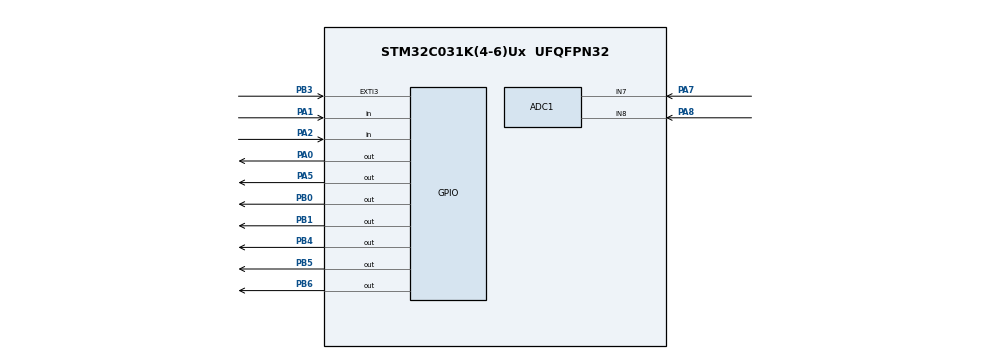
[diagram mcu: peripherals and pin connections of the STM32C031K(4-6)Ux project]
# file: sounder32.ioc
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ADC1.Channel-0\#ChannelRegularConversion=ADC_CHANNEL_7
ADC1.NbrOfConversionFlag=1
ADC1.Rank-0\#ChannelRegularConversion=1
ADC1.SamplingTime-0\#ChannelRegularConversion=ADC_SAMPLINGTIME_COMMON_1
ADC1.SelectedChannel=ADC_CHANNEL_7|ADC_CHANNEL_8
ADC1.master=1
Mcu.Family=STM32C0
Mcu.Name=STM32C031K(4-6)Ux
Mcu.Package=UFQFPN32
PA0.Signal=GPIO_Output
PA1.Signal=GPIO_Input
PA2.Signal=GPIO_Input
PA5.Signal=GPIO_Output
PA7.Mode=IN7
PA7.Signal=ADC1_IN7
PA8.Mode=IN8
PA8.Signal=ADC1_IN8
PB0.Signal=GPIO_Output
PB1.Signal=GPIO_Output
PB3.Signal=GPXTI3
PB4.Signal=GPIO_Output
PB5.Signal=GPIO_Output
PB6.Signal=GPIO_Output
PB7.Signal=I2C1_SDA
PB8.Signal=I2C1_SCL
ProjectManager.HeapSize=0x200
ProjectManager.StackSize=0x400
ProjectManager.TargetToolchain=MDK-ARM V5.32
RCC.ADCFreq_Value=12000000
RCC.AHBFreq_Value=12000000
RCC.CortexFreq_Value=12000000
RCC.EXTERNAL_CLOCK_VALUE=12288000
RCC.HCLKFreq_Value=12000000
RCC.HSE_VALUE=8000000
RCC.HSI_VALUE=48000000
RCC.LSE_VALUE=32768
RCC.SYSCLKFreq_VALUE=12000000
TIM1.Channel-Output\ Compare1\ No\ Output=TIM_CHANNEL_1
TIM3.Channel-Output\ Compare2\ No\ Output=TIM_CHANNEL_2
VP_TIM1_VS_ClockSourceINT.Mode=Internal
VP_TIM1_VS_no_output1.Mode=Output Compare1 No Output
VP_TIM3_VS_ClockSourceINT.Mode=Internal
VP_TIM3_VS_no_output2.Mode=Output Compare2 No Output
board=custom

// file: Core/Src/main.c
/* USER CODE BEGIN Header */
/**
  ******************************************************************************
  * @file           : main.c
  * @brief          : Main program body
  ******************************************************************************
  * @attention
  *
  * Copyright (c) 2023 STMicroelectronics.
  * All rights reserved.
  *
  * This software is licensed under terms that can be found in the LICENSE file
  * in the root directory of this software component.
  * If no LICENSE file comes with this software, it is provided AS-IS.
  *
  ******************************************************************************
  */
/* USER CODE END Header */
#include "main.h"

ADC_HandleTypeDef hadc1;

TIM_HandleTypeDef htim1;
TIM_HandleTypeDef htim3;

extern void main_8(void);

void SystemClock_Config(void);
static void MX_GPIO_Init(void);
static void MX_ADC1_Init(void);
static void MX_TIM3_Init(void);
static void MX_TIM1_Init(void);

int main(void)
{

  /* MCU Configuration--------------------------------------------------------*/

  /* Reset of all peripherals, Initializes the Flash interface and the Systick. */
  HAL_Init();

  /* Configure the system clock */
  SystemClock_Config();

  /* Initialize all configured peripherals */
  MX_GPIO_Init();
  MX_ADC1_Init();
  MX_TIM3_Init();
  MX_TIM1_Init();
  /* USER CODE BEGIN 2 */

	main_8();

  /* USER CODE END 2 */

  /* Infinite loop */
  while (1)
  {

  }
}

void SystemClock_Config(void)
{
  RCC_OscInitTypeDef RCC_OscInitStruct = {0};
  RCC_ClkInitTypeDef RCC_ClkInitStruct = {0};

  /** Initializes the RCC Oscillators according to the specified parameters
  * in the RCC_OscInitTypeDef structure.
  */
  RCC_OscInitStruct.OscillatorType = RCC_OSCILLATORTYPE_HSI;
  RCC_OscInitStruct.HSIState = RCC_HSI_ON;
  RCC_OscInitStruct.HSIDiv = RCC_HSI_DIV4;
  RCC_OscInitStruct.HSICalibrationValue = RCC_HSICALIBRATION_DEFAULT;
  if (HAL_RCC_OscConfig(&RCC_OscInitStruct) != HAL_OK)
  {
    Error_Handler();
  }

  /** Initializes the CPU, AHB and APB buses clocks
  */
  RCC_ClkInitStruct.ClockType = RCC_CLOCKTYPE_HCLK|RCC_CLOCKTYPE_SYSCLK
                              |RCC_CLOCKTYPE_PCLK1;
  RCC_ClkInitStruct.SYSCLKSource = RCC_SYSCLKSOURCE_HSI;
  RCC_ClkInitStruct.SYSCLKDivider = RCC_SYSCLK_DIV1;
  RCC_ClkInitStruct.AHBCLKDivider = RCC_HCLK_DIV1;
  RCC_ClkInitStruct.APB1CLKDivider = RCC_APB1_DIV1;

  if (HAL_RCC_ClockConfig(&RCC_ClkInitStruct, FLASH_LATENCY_0) != HAL_OK)
  {
    Error_Handler();
  }
}

static void MX_ADC1_Init(void)
{

  ADC_ChannelConfTypeDef sConfig = {0};

  /** Configure the global features of the ADC (Clock, Resolution, Data Alignment and number of conversion)
  */
  hadc1.Instance = ADC1;
  hadc1.Init.ClockPrescaler = ADC_CLOCK_SYNC_PCLK_DIV2;
  hadc1.Init.Resolution = ADC_RESOLUTION_12B;
  hadc1.Init.DataAlign = ADC_DATAALIGN_RIGHT;
  hadc1.Init.ScanConvMode = ADC_SCAN_DISABLE;
  hadc1.Init.EOCSelection = ADC_EOC_SINGLE_CONV;
  hadc1.Init.LowPowerAutoWait = DISABLE;
  hadc1.Init.LowPowerAutoPowerOff = DISABLE;
  hadc1.Init.ContinuousConvMode = DISABLE;
  hadc1.Init.NbrOfConversion = 1;
  hadc1.Init.DiscontinuousConvMode = DISABLE;
  hadc1.Init.ExternalTrigConv = ADC_SOFTWARE_START;
  hadc1.Init.ExternalTrigConvEdge = ADC_EXTERNALTRIGCONVEDGE_NONE;
  hadc1.Init.DMAContinuousRequests = DISABLE;
  hadc1.Init.Overrun = ADC_OVR_DATA_PRESERVED;
  hadc1.Init.SamplingTimeCommon1 = ADC_SAMPLETIME_1CYCLE_5;
  hadc1.Init.SamplingTimeCommon2 = ADC_SAMPLETIME_1CYCLE_5;
  hadc1.Init.OversamplingMode = DISABLE;
  hadc1.Init.TriggerFrequencyMode = ADC_TRIGGER_FREQ_HIGH;
  if (HAL_ADC_Init(&hadc1) != HAL_OK)
  {
    Error_Handler();
  }

  /** Configure Regular Channel
  */
  sConfig.Channel = ADC_CHANNEL_7;
  sConfig.Rank = ADC_REGULAR_RANK_1;
  sConfig.SamplingTime = ADC_SAMPLINGTIME_COMMON_1;
  if (HAL_ADC_ConfigChannel(&hadc1, &sConfig) != HAL_OK)
  {
    Error_Handler();
  }

}

static void MX_TIM1_Init(void)
{

  TIM_ClockConfigTypeDef sClockSourceConfig = {0};
  TIM_MasterConfigTypeDef sMasterConfig = {0};
  TIM_OC_InitTypeDef sConfigOC = {0};
  TIM_BreakDeadTimeConfigTypeDef sBreakDeadTimeConfig = {0};

  htim1.Instance = TIM1;
  htim1.Init.Prescaler = 0;
  htim1.Init.CounterMode = TIM_COUNTERMODE_UP;
  htim1.Init.Period = 65535;
  htim1.Init.ClockDivision = TIM_CLOCKDIVISION_DIV1;
  htim1.Init.RepetitionCounter = 0;
  htim1.Init.AutoReloadPreload = TIM_AUTORELOAD_PRELOAD_DISABLE;
  if (HAL_TIM_Base_Init(&htim1) != HAL_OK)
  {
    Error_Handler();
  }
  sClockSourceConfig.ClockSource = TIM_CLOCKSOURCE_INTERNAL;
  if (HAL_TIM_ConfigClockSource(&htim1, &sClockSourceConfig) != HAL_OK)
  {
    Error_Handler();
  }
  if (HAL_TIM_OC_Init(&htim1) != HAL_OK)
  {
    Error_Handler();
  }
  sMasterConfig.MasterOutputTrigger = TIM_TRGO_RESET;
  sMasterConfig.MasterOutputTrigger2 = TIM_TRGO2_RESET;
  sMasterConfig.MasterSlaveMode = TIM_MASTERSLAVEMODE_DISABLE;
  if (HAL_TIMEx_MasterConfigSynchronization(&htim1, &sMasterConfig) != HAL_OK)
  {
    Error_Handler();
  }
  sConfigOC.OCMode = TIM_OCMODE_TIMING;
  sConfigOC.Pulse = 0;
  sConfigOC.OCPolarity = TIM_OCPOLARITY_HIGH;
  sConfigOC.OCNPolarity = TIM_OCNPOLARITY_HIGH;
  sConfigOC.OCFastMode = TIM_OCFAST_DISABLE;
  sConfigOC.OCIdleState = TIM_OCIDLESTATE_RESET;
  sConfigOC.OCNIdleState = TIM_OCNIDLESTATE_RESET;
  if (HAL_TIM_OC_ConfigChannel(&htim1, &sConfigOC, TIM_CHANNEL_1) != HAL_OK)
  {
    Error_Handler();
  }
  sBreakDeadTimeConfig.OffStateRunMode = TIM_OSSR_DISABLE;
  sBreakDeadTimeConfig.OffStateIDLEMode = TIM_OSSI_DISABLE;
  sBreakDeadTimeConfig.LockLevel = TIM_LOCKLEVEL_OFF;
  sBreakDeadTimeConfig.DeadTime = 0;
  sBreakDeadTimeConfig.BreakState = TIM_BREAK_DISABLE;
  sBreakDeadTimeConfig.BreakPolarity = TIM_BREAKPOLARITY_HIGH;
  sBreakDeadTimeConfig.BreakFilter = 0;
  sBreakDeadTimeConfig.BreakAFMode = TIM_BREAK_AFMODE_INPUT;
  sBreakDeadTimeConfig.Break2State = TIM_BREAK2_DISABLE;
  sBreakDeadTimeConfig.Break2Polarity = TIM_BREAK2POLARITY_HIGH;
  sBreakDeadTimeConfig.Break2Filter = 0;
  sBreakDeadTimeConfig.Break2AFMode = TIM_BREAK_AFMODE_INPUT;
  sBreakDeadTimeConfig.AutomaticOutput = TIM_AUTOMATICOUTPUT_DISABLE;
  if (HAL_TIMEx_ConfigBreakDeadTime(&htim1, &sBreakDeadTimeConfig) != HAL_OK)
  {
    Error_Handler();
  }

}

static void MX_TIM3_Init(void)
{

  TIM_ClockConfigTypeDef sClockSourceConfig = {0};
  TIM_MasterConfigTypeDef sMasterConfig = {0};
  TIM_OC_InitTypeDef sConfigOC = {0};

  htim3.Instance = TIM3;
  htim3.Init.Prescaler = 0;
  htim3.Init.CounterMode = TIM_COUNTERMODE_UP;
  htim3.Init.Period = 65535;
  htim3.Init.ClockDivision = TIM_CLOCKDIVISION_DIV1;
  htim3.Init.AutoReloadPreload = TIM_AUTORELOAD_PRELOAD_DISABLE;
  if (HAL_TIM_Base_Init(&htim3) != HAL_OK)
  {
    Error_Handler();
  }
  sClockSourceConfig.ClockSource = TIM_CLOCKSOURCE_INTERNAL;
  if (HAL_TIM_ConfigClockSource(&htim3, &sClockSourceConfig) != HAL_OK)
  {
    Error_Handler();
  }
  if (HAL_TIM_OC_Init(&htim3) != HAL_OK)
  {
    Error_Handler();
  }
  sMasterConfig.MasterOutputTrigger = TIM_TRGO_RESET;
  sMasterConfig.MasterSlaveMode = TIM_MASTERSLAVEMODE_DISABLE;
  if (HAL_TIMEx_MasterConfigSynchronization(&htim3, &sMasterConfig) != HAL_OK)
  {
    Error_Handler();
  }
  sConfigOC.OCMode = TIM_OCMODE_TIMING;
  sConfigOC.Pulse = 0;
  sConfigOC.OCPolarity = TIM_OCPOLARITY_HIGH;
  sConfigOC.OCFastMode = TIM_OCFAST_DISABLE;
  if (HAL_TIM_OC_ConfigChannel(&htim3, &sConfigOC, TIM_CHANNEL_2) != HAL_OK)
  {
    Error_Handler();
  }

}

static void MX_GPIO_Init(void)
{
  GPIO_InitTypeDef GPIO_InitStruct = {0};

  /* GPIO Ports Clock Enable */
  __HAL_RCC_GPIOA_CLK_ENABLE();
  __HAL_RCC_GPIOB_CLK_ENABLE();

  /*Configure GPIO pin Output Level */
  HAL_GPIO_WritePin(GPIOA, GPIO_PIN_0|GPIO_PIN_5, GPIO_PIN_RESET);

  /*Configure GPIO pin Output Level */
  HAL_GPIO_WritePin(GPIOB, GPIO_PIN_0|GPIO_PIN_1|GPIO_PIN_4|GPIO_PIN_5
                          |GPIO_PIN_6, GPIO_PIN_RESET);

  /*Configure GPIO pins : PA0 PA5 */
  GPIO_InitStruct.Pin = GPIO_PIN_0|GPIO_PIN_5;
  GPIO_InitStruct.Mode = GPIO_MODE_OUTPUT_PP;
  GPIO_InitStruct.Pull = GPIO_NOPULL;
  GPIO_InitStruct.Speed = GPIO_SPEED_FREQ_LOW;
  HAL_GPIO_Init(GPIOA, &GPIO_InitStruct);

  /*Configure GPIO pins : PA1 PA2 */
  GPIO_InitStruct.Pin = GPIO_PIN_1|GPIO_PIN_2;
  GPIO_InitStruct.Mode = GPIO_MODE_INPUT;
  GPIO_InitStruct.Pull = GPIO_NOPULL;
  HAL_GPIO_Init(GPIOA, &GPIO_InitStruct);

  /*Configure GPIO pins : PB0 PB1 PB4 PB5
                           PB6 */
  GPIO_InitStruct.Pin = GPIO_PIN_0|GPIO_PIN_1|GPIO_PIN_4|GPIO_PIN_5
                          |GPIO_PIN_6;
  GPIO_InitStruct.Mode = GPIO_MODE_OUTPUT_PP;
  GPIO_InitStruct.Pull = GPIO_NOPULL;
  GPIO_InitStruct.Speed = GPIO_SPEED_FREQ_LOW;
  HAL_GPIO_Init(GPIOB, &GPIO_InitStruct);

  /*Configure GPIO pin : PB3 */
  GPIO_InitStruct.Pin = GPIO_PIN_3;
  GPIO_InitStruct.Mode = GPIO_MODE_IT_RISING;
  GPIO_InitStruct.Pull = GPIO_NOPULL;
  HAL_GPIO_Init(GPIOB, &GPIO_InitStruct);

  /*Configure GPIO pins : PB7 PB8 */
  GPIO_InitStruct.Pin = GPIO_PIN_7|GPIO_PIN_8;
  GPIO_InitStruct.Mode = GPIO_MODE_AF_OD;
  GPIO_InitStruct.Pull = GPIO_NOPULL;
  GPIO_InitStruct.Speed = GPIO_SPEED_FREQ_LOW;
  GPIO_InitStruct.Alternate = GPIO_AF6_I2C1;
  HAL_GPIO_Init(GPIOB, &GPIO_InitStruct);

}

void Error_Handler(void)
{
  __disable_irq();
  while (1)
  {
  }
}
